# MCRC0_MCRC0 register map
Vendor: Texas Instruments
Peripheral module from a debugger description file (folder AM263).
Registers are 32-bit, read-only, reset 0x0 unless marked. A register's access mark holds for its fields unless they carry their own. Offsets are as the file gives them; lines under a group give offsets from that group; [hi:lo] are bit positions; {n}, {i} and the like mark numbered series; 'fields as' and 'values as' point back to an identical list; <NAME> marks a mode.

## MCRC0_MCRC0
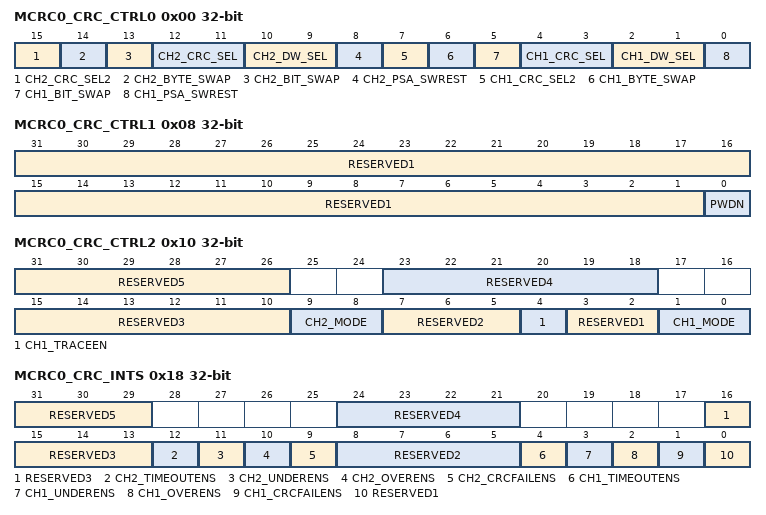
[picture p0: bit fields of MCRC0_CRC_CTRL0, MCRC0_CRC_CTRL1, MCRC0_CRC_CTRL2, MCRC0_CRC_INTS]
0x00 MCRC0_CRC_CTRL0 rw
  [15] CH2_CRC_SEL2 — Refer 'CH2_DW_SEL' field description
  [14] CH2_BYTE_SWAP — BYTE SWAP Enable across Data Size0 ? Byte Swap Disabled1 ? Byte Swap enabled.
  [13] CH2_BIT_SWAP — msb/lsb SWAPPING 0 ? msb (most significant bit First)1 ? lsb (least significant bit First)
  [12:11] CH2_CRC_SEL — CRC type select. {CH1_CRC_SEL2,CH1_CRC_SEL[1:0]}000 ? CRC-64001 - CRC-16010 ? CRC-32100 - VDA CAN, SAE-J1850 CRC-8101 - H2F, Autosar 4.0110 - CASTAGNOLI, iSCSI111 / 011 - E2E Profile 4
  [10:9] CH2_DW_SEL — CRC Data Size select.000 ? 64 bit Data Size001 - 16 bit Data Size010 ? 32 Bit Data Size
  [8] CH2_PSA_SWREST — Channel 2 PSA Software Reset. When set, the PSA SignatureRegister is reset to all zero. Software reset does not reset softwarereset bit itself. Therefore, CPU is required to clear this bit by writinga ?0?.0 = PSA Signature Register not reset1 = PSA Signature Register reset
  [7] CH1_CRC_SEL2 — Refer 'CH1_DW_SEL' field description
  [6] CH1_BYTE_SWAP — BYTE SWAP Enable across Data Size0 ? Byte Swap Disabled1 ? Byte Swap enabled.
  [5] CH1_BIT_SWAP — msb/lsb SWAPPING 0 ? msb (most significant bit First)1 ? lsb (least significant bit First)
  [4:3] CH1_CRC_SEL — CRC type select. {CH1_CRC_SEL2,CH1_CRC_SEL[1:0]}000 ? CRC-64001 - CRC-16010 ? CRC-32100 - VDA CAN, SAE-J1850 CRC-8101 - H2F, Autosar 4.0110 - CASTAGNOLI, iSCSI111 / 011 - E2E Profile 4
  [2:1] CH1_DW_SEL — CRC Data Size select.000 ? 64 bit Data Size001 - 16 bit Data Size010 ? 32 Bit Data Size
  [0] CH1_PSA_SWREST — Channel 1 PSA Software Reset. When set, the PSA SignatureRegister is reset to all zero. Software reset does not reset softwarereset bit itself. Therefore, CPU is required to clear this bit by writinga ?0?.0 = PSA Signature Register not reset1 = PSA Signature Register reset
0x08 MCRC0_CRC_CTRL1 access per field
  [31:1] RESERVED1 ro — Not Defined
  [0] PWDN rw — Power Down. When set, MCRC moduleMCRC Module is put inpower down mode.0 = MCRC is not in power down mode1 = MCRC is in power down mode
0x10 MCRC0_CRC_CTRL2 access per field
  [31:26] RESERVED5 ro — Not Defined
  [23:18] RESERVED4 ro — Not Defined
  [15:10] RESERVED3 ro — Not Defined
  [9:8] CH2_MODE rw — Channel 2 Mode:0 0 = Data Capture mode. In this mode, the PSA Signature Registerdoes not compress data when it is written. Any datawritten to PSA Signature Register is simply captured byPSA Signature Register without any compression. Thismode can be used to plant seed value into the PSA register0 1 = AUTO mode1 0 = reserved1 1 = Full-CPU mode
  [7:5] RESERVED2 ro — Not Defined
  [4] CH1_TRACEEN rw — Channel 1 Data Trace Enable. When set, the channel is put intodata trace mode. The channel snoops on the CPU VBUSM,ITCM, DTCM buses for any read transaction. Any read data onthese buses is compressed by the PSA Signature Register. Whensuspend is on, the PSA Signature Register does not compress anyread data on these buses.0 = Data Trace disable1 = Data Trace enable
  [3:2] RESERVED1 ro — Not Defined
  [1:0] CH1_MODE rw — Channel 1 Mode:0 0 = Data Capture mode. In this mode, the PSA Signature Registerdoes not compress data when it is written. Any datawritten to PSA Signature Register is simply captured byPSA Signature Register without any compression. Thismode can be used to plant seed value into the PSA register0 1 = AUTO mode1 0 = reserved1 1 = Full-CPU mode
0x18 MCRC0_CRC_INTS access per field
  [31:29] RESERVED5 ro — Not Defined
  [24:21] RESERVED4 ro — Not Defined
  [16:13] RESERVED3 ro — Not Defined
  [12] CH2_TIMEOUTENS rw — Channel 2 Timeout Interrupt Enable Bit. Writing a one to thisbit enable the timeout interrupt. Writing a zero has no effect.Reading from this bit gives the status (interrupt enable/disable).User and privileged mode read:0 = Timeout Interrupt disable1 = Timeout Interrupt enableUser and privileged mode write:0 = Has no effect1 = Timeout Interrupt enable
  [11] CH2_UNDERENS rw — Channel 2 Underrun Interrupt Enable Bit. Writing a one tothis bit enable the underrun interrupt. Writing a zero has no effect.Reading from this bit gives the status (interrupt enable/disable).User and privileged mode read:0 = Underrun Interrupt disable1 = Underrun Interrupt enableUser and privileged mode write:0 = Has no effect1 = Underrun Interrupt enable
  [10] CH2_OVERENS rw — Channel 2 Overrun Interrupt Enable Bit. Writing a one to thisbit enable the overrun interrupt. Writing a zero has no effect.Reading from this bit gives the status (interrupt enable/disable).User and privileged mode read:0 = Overrun Interrupt disable1 = Overrun Interrupt enableUser and privileged mode write:0 = Has no effect1 = Overrun Interrupt enable
  [9] CH2_CRCFAILENS rw — Channel 2 CRC Fail Interrupt Enable Bit. Writing a one to thisbit enable the CRC fail interrupt. Writing a zero has no effect.Reading from this bit gives the status (interrupt enable/disable).User and privileged mode read:0 = CRC Fail Interrupt disable1 = CRC Fail Interrupt enableUser and privileged mode write:0 = Has no effect1 = CRC Fail Interrupt enable
  [8:5] RESERVED2 ro — Not Defined
  [4] CH1_TIMEOUTENS rw — Channel 1 Timeout Interrupt Enable Bit. Writing a one to thisbit enable the timeout interrupt. Writing a zero has no effect.Reading from this bit gives the status (interrupt enable/disable).User and privileged mode read:0 = Timeout Interrupt disable1 = Timeout Interrupt enableUser and privileged mode write:0 = Has no effect1 = Timeout Interrupt enable
  [3] CH1_UNDERENS rw — Channel 1 Underrun Interrupt Enable Bit. Writing a one tothis bit enable the underrun interrupt. Writing a zero has no effect.Reading from this bit gives the status (interrupt enable/disable).User and privileged mode read:0 = Underrun Interrupt disable1 = Underrun Interrupt enableUser and privileged mode write:0 = Has no effect1 = Underrun Interrupt enable
  [2] CH1_OVERENS rw — Channel 1 Overrun Interrupt Enable Bit. Writing a one to thisbit enable the overrun interrupt. Writing a zero has no effect.Reading from this bit gives the status (interrupt enable/disable).User and privileged mode read:0 = Overrun Interrupt disable1 = Overrun Interrupt enableUser and privileged mode write:0 = Has no effect1 = Overrun Interrupt enable
  [1] CH1_CRCFAILENS rw — Channel 1 CRC Fail Interrupt Enable Bit. Writing a one to thisbit enable the CRC fail interrupt. Writing a zero has no effect.Reading from this bit gives the status (interrupt enable/disable).User and privileged mode read:0 = CRC Fail Interrupt disable1 = CRC Fail Interrupt enableUser and privileged mode write:0 = Has no effect1 = CRC Fail Interrupt enable
  [0] RESERVED1 ro — Not Defined
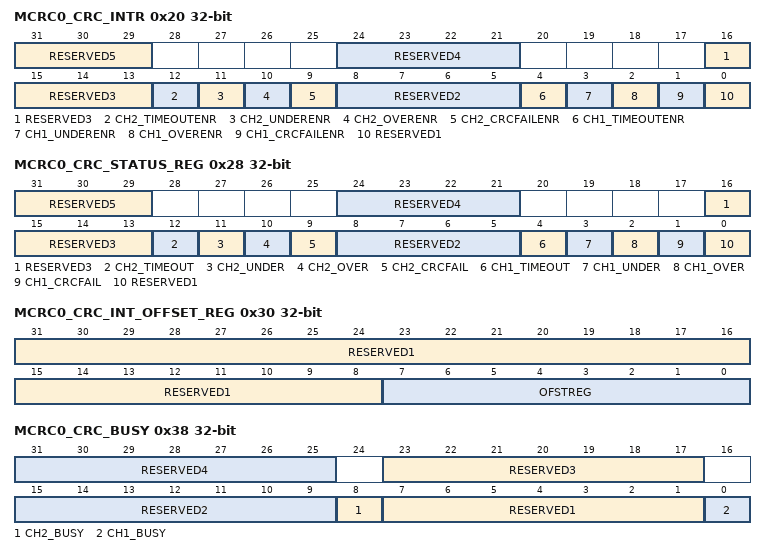
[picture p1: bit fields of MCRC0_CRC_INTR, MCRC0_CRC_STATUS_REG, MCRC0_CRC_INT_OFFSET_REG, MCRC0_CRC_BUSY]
0x20 MCRC0_CRC_INTR access per field
  [31:29] RESERVED5 ro — Not Defined
  [24:21] RESERVED4 ro — Not Defined
  [16:13] RESERVED3 ro — Not Defined
  [12] CH2_TIMEOUTENR rw — Channel 2 Timeout Interrupt Disable Bit. Writing a one to thisbit disable the timeout interrupt. Writing a zero has no effect.Reading from this bit gives the status (interrupt enable/disable).User and privileged mode read:0 = Timeout Interrupt disable1 = Timeout Interrupt enableUser and privileged mode write:0 = Has no effect1 = Timeout Interrupt disable
  [11] CH2_UNDERENR rw — Channel 2 Underrun Interrupt Disable Bit. Writing a one tothis bit disable the underrun interrupt. Writing a zero has noeffect. Reading from this bit gives the status (interrupt enable/dis-able).User and privileged mode read:0 = Underrun Interrupt disable1 = Underrun Interrupt enableUser and privileged mode write:0 = Has no effect1 = Underrun Interrupt disable
  [10] CH2_OVERENR rw — Channel 2 Overrun Interrupt Disable Bit. Writing a one to thisbit disable the overrun interrupt. Writing a zero has no effect.Reading from this bit gives the status (interrupt enable/disable).User and privileged mode read:0 = Overrun Interrupt disable1 = Overrun Interrupt enableUser and privileged mode write:0 = Has no effect1 = Overrun Interrupt disable
  [9] CH2_CRCFAILENR rw — Channel 2 CRC Fail Interrupt Disable Bit. Writing a one to thisbit disable the CRC fail interrupt. Writing a zero has no effect.Reading from this bit gives the status (interrupt enable/disable).User and privileged mode read:0 = CRC Fail Interrupt disable1 = CRC Fail Interrupt enableUser and privileged mode write:0 = Has no effect1 = CRC Fail Interrupt disable
  [8:5] RESERVED2 ro — Not Defined
  [4] CH1_TIMEOUTENR rw — Channel 1 Timeout Interrupt Disable Bit. Writing a one to thisbit disable the timeout interrupt. Writing a zero has no effect.Reading from this bit gives the status (interrupt enable/disable).User and privileged mode read:0 = Timeout Interrupt disable1 = Timeout Interrupt enableUser and privileged mode write:0 = Has no effect1 = Timeout Interrupt disable
  [3] CH1_UNDERENR rw — Channel 1 Underrun Interrupt Disable Bit. Writing a one tothis bit disable the underrun interrupt. Writing a zero has noeffect. Reading from this bit gives the status (interrupt enable/dis-able).User and privileged mode read:0 = Underrun Interrupt disable1 = Underrun Interrupt enableUser and privileged mode write:0 = Has no effect1 = Underrun Interrupt disable
  [2] CH1_OVERENR rw — Channel 1 Overrun Interrupt Disable Bit. Writing a one to thisbit disable the overrun interrupt. Writing a zero has no effect.Reading from this bit gives the status (interrupt enable/disable).User and privileged mode read:0 = Overrun Interrupt disable1 = Overrun Interrupt enableUser and privileged mode write:0 = Has no effect1 = Overrun Interrupt disable
  [1] CH1_CRCFAILENR rw — Channel 1 CRC Fail Interrupt Disable Bit. Writing a one to thisbit disable the CRC fail interrupt. Writing a zero has no effect.Reading from this bit gives the status (interrupt enable/disable).User and privileged mode read:0 = CRC Fail Interrupt disable1 = CRC Fail Interrupt enableUser and privileged mode write:0 = Has no effect1 = CRC Fail Interrupt disable
  [0] RESERVED1 ro — Not Defined
0x28 MCRC0_CRC_STATUS_REG access per field
  [31:29] RESERVED5 ro — Not Defined
  [24:21] RESERVED4 ro — Not Defined
  [16:13] RESERVED3 ro — Not Defined
  [12] CH2_TIMEOUT rw — Channel 2 CRC Timeout Status Flag. This bit is cleared bywriting a ?1? to it only. Writing ?0? has no effect. This bit is set inAUTO mode.0 = No timeout interrupt is active1 = Timeout interrupt is active
  [11] CH2_UNDER rw — Channel 2 CRC Underrun Status Flag. This bit is cleared bywriting a ?1? to it only. Writing ?0? has no effect. This bit is set inAUTO mode only0 = No underrun interrupt is active1 = Underrun interrupt is active
  [10] CH2_OVER rw — Channel 2 CRC Overrun Status Flag. This bit is cleared bywriting a ?1? to it only. Writing ?0? has no effect. This bit is set inAUTO mode0 = No overrun interrupt is active1 = Overrun interrupt is active
  [9] CH2_CRCFAIL rw — Channel 2 CRC Compare Fail Status Flag. This bit is clearedby writing a ?1? to it only. Writing ?0? has no effect. This bit is setin AUTO mode only.0 = No CRC compare fail interrupt is active1 = CRC compare fail interrupt is active
  [8:5] RESERVED2 ro — Not Defined
  [4] CH1_TIMEOUT rw — Channel 1 CRC Timeout Status Flag. This bit is cleared bywriting a ?1? to it only. Writing ?0? has no effect. This bit is set inAUTO mode.0 = No timeout interrupt is active1 = Timeout interrupt is active
  [3] CH1_UNDER rw — Channel 1 CRC Underrun Status Flag. This bit is cleared bywriting a ?1? to it only. Writing ?0? has no effect. This bit is set inAUTO mode only0 = No underrun interrupt is active1 = Underrun interrupt is active
  [2] CH1_OVER rw — Channel 1 CRC Overrun Status Flag. This bit is cleared bywriting a ?1? to it only. Writing ?0? has no effect. This bit is set inAUTO mode0 = No overrun interrupt is active1 = Overrun interrupt is active
  [1] CH1_CRCFAIL rw — Channel 1 CRC Compare Fail Status Flag. This bit is clearedby writing a ?1? to it only. Writing ?0? has no effect. This bit is setin AUTO mode only.0 = No CRC compare fail interrupt is active1 = CRC compare fail interrupt is active
  [0] RESERVED1 ro — Not Defined
0x30 MCRC0_CRC_INT_OFFSET_REG access per field
  [31:8] RESERVED1 ro — Not Defined
  [7:0] OFSTREG rw — CRC Interrupt Offset. This register indicates the highest prioritypending interrupt vector address. Reading the offset register auto-matically clear the respective interrupt flag. Please referenceTable 1?3. for details.
0x38 MCRC0_CRC_BUSY
  [8n-1:8n-7] RESERVED{n} (n=1..4) — Not Defined
  [8] CH2_BUSY — Ch2_BUSY. During AUTO mode, the busy flag is set when thefirst data pattern of the block is compressed and remains set untilthe the last data pattern of the block is compressed. The flag iscleared when the last data pattern of the block is compressed.
  [0] CH1_BUSY — CH1_BUSY. During AUTO mode, the busy flag is set when thefirst data pattern of the block is compressed and remains set untilthe the last data pattern of the block is compressed. The flag iscleared when the last data pattern of the block is compressed.
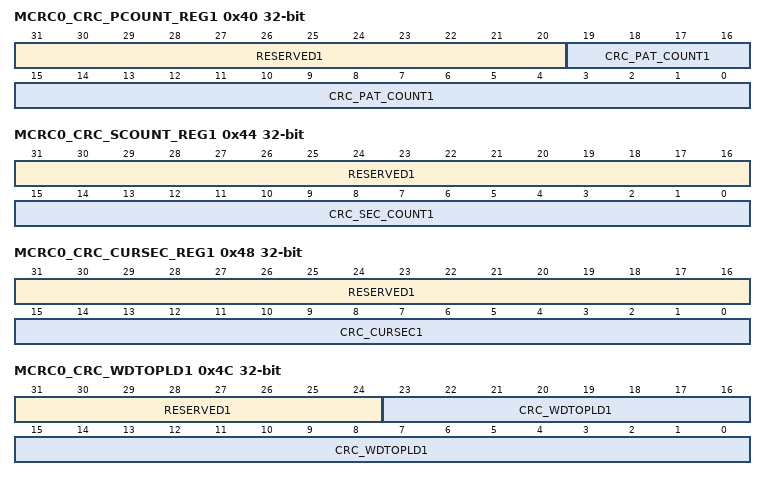
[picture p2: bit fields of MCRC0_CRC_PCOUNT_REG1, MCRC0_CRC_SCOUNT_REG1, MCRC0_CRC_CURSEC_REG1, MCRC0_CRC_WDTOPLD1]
0x40 MCRC0_CRC_PCOUNT_REG1 access per field
  [31:20] RESERVED1 ro — Not Defined
  [19:0] CRC_PAT_COUNT1 rw — Channel 1 Pattern Counter Preload Register. This register con-tains the number of data patterns in one sector to be compressedbefore a CRC is performed.
0x44 MCRC0_CRC_SCOUNT_REG1 access per field
  [31:16] RESERVED1 ro — Not Defined
  [15:0] CRC_SEC_COUNT1 rw — Channel 1 Sector Counter Preload Register. This register con-tains the number of sectors in one block of memory.
0x48 MCRC0_CRC_CURSEC_REG1 access per field
  [31:16] RESERVED1 ro — Not Defined
  [15:0] CRC_CURSEC1 rw — Channel 1 Current Sector ID Register. In AUTO mode, thisregister contains the current sector number of which the signatureverification fails. The sector counter is a free running up counter.When a sector fails, the erroneous sector number is logged intocurrent sector ID register and the CRC fail interrupt is generatedThe sector ID register is frozen until it is read and the CRC failstatus bit is cleared by CPU. While it is frozen, it does not captureanother erroneous sector number. When this condition happens,an overrun interrupt is generated instead. Once the register is readand the CRC fail interrupt flag is cleared it can capture new erro-neous sector number.
0x4C MCRC0_CRC_WDTOPLD1 access per field
  [31:24] RESERVED1 ro — Not Defined
  [23:0] CRC_WDTOPLD1 rw — Channel 1 Watchdog Timeout Counter Preload Register. Thisregister contains the number of clock cycles within which theDMA must transfer the next block of data patterns.
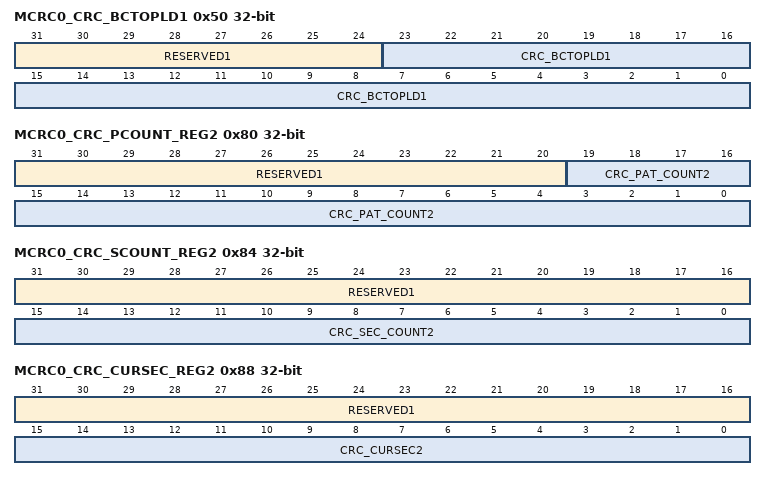
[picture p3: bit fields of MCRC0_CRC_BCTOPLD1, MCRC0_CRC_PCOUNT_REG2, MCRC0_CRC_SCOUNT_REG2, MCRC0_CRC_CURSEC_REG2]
0x50 MCRC0_CRC_BCTOPLD1 access per field
  [31:24] RESERVED1 ro — Not Defined
  [23:0] CRC_BCTOPLD1 rw — Channel 1 Block Complete Timeout Counter Preload Regis-ter. This register contains the number of clock cycles withinwhich the CRC for an entire block needs to complete before atimeout interrupt is generated.
0x60 MCRC0_PSA_SIGREGL1 rw
  [31:0] PSASIG1_31_0 — Channel 1 PSA Signature Low Register. This register containsthe value stored at PSASIG1[31:0] register.
0x64 MCRC0_PSA_SIGREGH1 rw
  [31:0] PSA_SIG1_63_32 — Channel 1 PSA Signature High Register. This register containsthe value stored at PSASIG1[63:32] register.
0x68 MCRC0_CRC_REGL1 rw
  [31:0] CRC1_31_0 — Channel 1 CRC Value Low Register. This register contains thecurrent known good signature value stored at CRC1[31:0] regis-ter.
0x6C MCRC0_CRC_REGH1 rw
  [31:0] CRC1_63_32 — Channel 1 CRC Value High Register. This register contains thecurrent known good signature value stored at CRC1[63:32] regis-ter.
0x70 MCRC0_PSA_SECSIGREGL1
  [31:0] PSASECSIG1_31_0 — Channel 1 PSA Sector Signature Low Register. This registercontains the value stored at PSASECSIG1[31:0] register.
0x74 MCRC0_PSA_SECSIGREGH1
  [31:0] PSASECSIG1_63_32 — Channel 1 PSA Sector Signature High Register. This registercontains the value stored at PSASECSIG1[63:32] register.
0x78 MCRC0_RAW_DATAREGL1
  [31:0] RAW_DATA1_31_0 — Channel 1 Raw Data Low Register. This register contains bit31:0 of the un-compressed raw data.
0x7C MCRC0_RAW_DATAREGH1
  [31:0] RAW_DATA1_63_32 — Channel 1 Raw Data High Register. This register contains bit63:32 of the un-compressed raw data.
0x80 MCRC0_CRC_PCOUNT_REG2 access per field
  [31:20] RESERVED1 ro — Not Defined
  [19:0] CRC_PAT_COUNT2 rw — Channel 2 Pattern Counter Preload Register. This register con-tains the number of data patterns in one sector to be compressedbefore a CRC is performed.
0x84 MCRC0_CRC_SCOUNT_REG2 access per field
  [31:16] RESERVED1 ro — Not Defined
  [15:0] CRC_SEC_COUNT2 rw — Channel 2 Sector Counter Preload Register. This register con-tains the number of sectors in one block of memory.
0x88 MCRC0_CRC_CURSEC_REG2 access per field
  [31:16] RESERVED1 ro — Not Defined
  [15:0] CRC_CURSEC2 rw — Channel 2 Current Sector ID Register. In AUTO mode, thisregister contains the current sector number of which the signatureverification fails. The sector counter is a free running up counter.When a sector fails, the erroneous sector number is logged intocurrent sector ID register and the CRC fail interrupt is generatedThe sector ID register is frozen until it is read and the CRC failstatus bit is cleared by CPU. While it is frozen, it does not captureanother erroneous sector number. When this condition happens,an overrun interrupt is generated instead. Once the register is readand the CRC fail interrupt flag is cleared it can capture new erro-neous sector number.
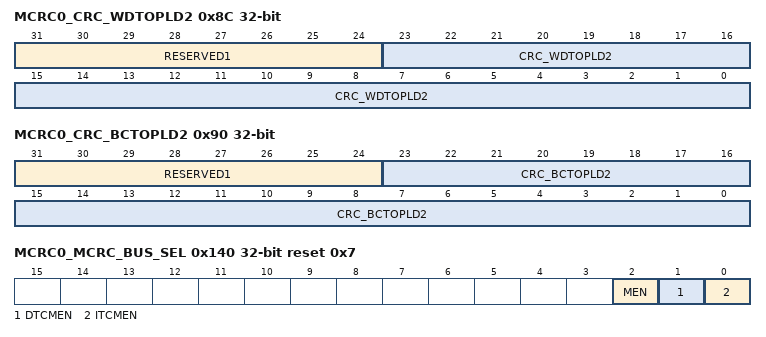
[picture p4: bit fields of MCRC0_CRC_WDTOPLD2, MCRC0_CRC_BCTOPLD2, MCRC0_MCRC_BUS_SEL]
0x8C MCRC0_CRC_WDTOPLD2 access per field
  [31:24] RESERVED1 ro — Not Defined
  [23:0] CRC_WDTOPLD2 rw — Channel 2 Watchdog Timeout Counter Preload Register. Thisregister contains the number of clock cycles within which theDMA must transfer the next block of data patterns.
0x90 MCRC0_CRC_BCTOPLD2 access per field
  [31:24] RESERVED1 ro — Not Defined
  [23:0] CRC_BCTOPLD2 rw — Channel 2 Block Complete Timeout Counter Preload Regis-ter. This register contains the number of clock cycles withinwhich the CRC for an entire block needs to complete before atimeout interrupt is generated.
0xA0 MCRC0_PSA_SIGREGL2 rw
  [31:0] PSASIG2_31_0 — Channel 2 PSA Signature Low Register. This register containsthe value stored at PSASIG2[31:0] register.
0xA4 MCRC0_PSA_SIGREGH2 rw
  [31:0] PSA_SIG2_63_32 — Channel 2 PSA Signature High Register. This register containsthe value stored at PSASIG2[63:32] register.
0xA8 MCRC0_CRC_REGL2 rw
  [31:0] CRC2_31_0 — Channel 2 CRC Value Low Register. This register contains thecurrent known good signature value stored at CRC2[31:0] regis-ter.
0xAC MCRC0_CRC_REGH2 rw
  [31:0] CRC2_63_32 — Channel 2 CRC Value High Register. This register contains thecurrent known good signature value stored at CRC2[63:32] regis-ter.
0xB0 MCRC0_PSA_SECSIGREGL2
  [31:0] PSASECSIG2_31_0 — Channel 2 PSA Sector Signature Low Register. This registercontains the value stored at PSASECSIG2[31:0] register.
0xB4 MCRC0_PSA_SECSIGREGH2
  [31:0] PSASECSIG2_63_32 — Channel 2 PSA Sector Signature High Register. This registercontains the value stored at PSASECSIG2[63:32] register.
0xB8 MCRC0_RAW_DATAREGL2
  [31:0] RAW_DATA2_31_0 — Channel 2 Raw Data Low Register. This register contains bit31:0 of the un-compressed raw data.
0xBC MCRC0_RAW_DATAREGH2
  [31:0] RAW_DATA2_63_32 — Channel 2 Raw Data High Register. This register contains bit63:32 of the un-compressed raw data.
0xC0 MCRC0_CRC_PCOUNT_REG3
  [31:20] RESERVED1 — Not Defined
0xC4 MCRC0_CRC_SCOUNT_REG3
  [31:16] RESERVED1 — Not Defined
0xC8 MCRC0_CRC_CURSEC_REG3
  [31:16] RESERVED1 — Not Defined
0xCC MCRC0_CRC_WDTOPLD3
  [31:24] RESERVED1 — Not Defined
0xD0 MCRC0_CRC_BCTOPLD3
  [31:24] RESERVED1 — Not Defined
0xE0 MCRC0_PSA_SIGREGL3 access not given reset not defined
0xE4 MCRC0_PSA_SIGREGH3 access not given reset not defined
0xE8 MCRC0_CRC_REGL3 access not given reset not defined
0xEC MCRC0_CRC_REGH3 access not given reset not defined
0xF0 MCRC0_PSA_SECSIGREGL3 access not given reset not defined
0xF4 MCRC0_PSA_SECSIGREGH3 access not given reset not defined
0xF8 MCRC0_RAW_DATAREGL3 access not given reset not defined
0xFC MCRC0_RAW_DATAREGH3 access not given reset not defined
0x100 MCRC0_CRC_PCOUNT_REG4
  [31:20] RESERVED1 — Not Defined
0x104 MCRC0_CRC_SCOUNT_REG4
  [31:16] RESERVED1 — Not Defined
0x108 MCRC0_CRC_CURSEC_REG4
  [31:16] RESERVED1 — Not Defined
0x10C MCRC0_CRC_WDTOPLD4
  [31:24] RESERVED1 — Not Defined
0x110 MCRC0_CRC_BCTOPLD4
  [31:24] RESERVED1 — Not Defined
0x120 MCRC0_PSA_SIGREGL4 access not given reset not defined
0x124 MCRC0_PSA_SIGREGH4 access not given reset not defined
0x128 MCRC0_CRC_REGL4 access not given reset not defined
0x12C MCRC0_CRC_REGH4 access not given reset not defined
0x130 MCRC0_PSA_SECSIGREGL4 access not given reset not defined
0x134 MCRC0_PSA_SECSIGREGH4 access not given reset not defined
0x138 MCRC0_RAW_DATAREGL4 access not given reset not defined
0x13C MCRC0_RAW_DATAREGH4 access not given reset not defined
0x140 MCRC0_MCRC_BUS_SEL rw reset 0x7
  [2] MEN — MEn. Enable/disables the tracing of VBUSM 0: Tracing of VBUSM master bus has been disabled 1: Tracing of VBUSM master bus has been enabled
  [1] DTCMEN — DTCMEn. Enable/disables the tracing of data TCM0: Tracing of DTCM_ODD and DTCM_EVEN buses have been disabled1: Tracing of DTCM_ODD and DTCM_EVEN buses have been enabled
  [0] ITCMEN — ITCMEn. Enable/disables the tracing of instruction TCM 0: Tracing of ITCM bus has been disabled 1: Tracing of ITCM bus has been enabled
0x144 MCRC0_MCRC_RESERVED
  [31:0] NU68 — 0x144 to 0x1FF is reserved area.
